# STM32G474xx register map
File version: 1.4
CPU: CM4 r0p1, little endian, MPU, FPU, 4 interrupt priority bits
Registers are 32-bit, read-write, reset 0x0 unless marked. A register's access mark holds for its fields unless they carry their own. Offsets are from the block's base; [hi:lo] are bit positions; {n}, {i} and the like mark numbered series.

## FMAC — Filter Math Accelerator
Base 0x40021400
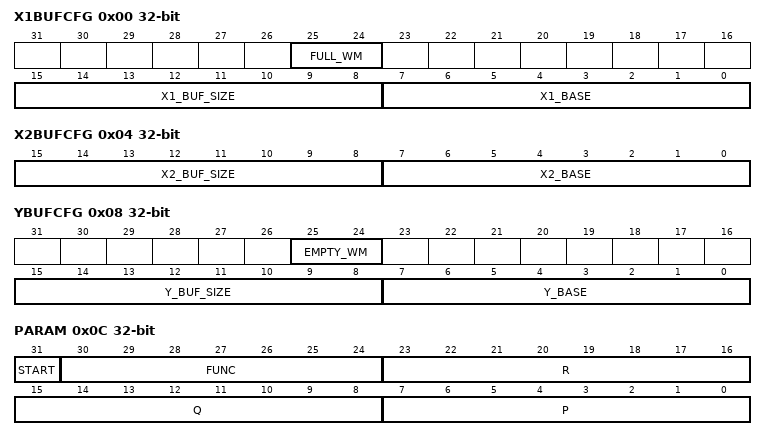
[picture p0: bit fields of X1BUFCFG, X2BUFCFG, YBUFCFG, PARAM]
0x00 X1BUFCFG — FMAC X1 Buffer Configuration register
  [25:24] FULL_WM, [15:8] X1_BUF_SIZE, [7:0] X1_BASE
0x04 X2BUFCFG — FMAC X2 Buffer Configuration register
  [15:8] X2_BUF_SIZE — X1_BUF_SIZE
  [7:0] X2_BASE — X1_BASE
0x08 YBUFCFG — FMAC Y Buffer Configuration register
  [25:24] EMPTY_WM
  [15:8] Y_BUF_SIZE — X1_BUF_SIZE
  [7:0] Y_BASE — X1_BASE
0x0C PARAM — FMAC Parameter register
  [31] START, [30:24] FUNC, [23:16] R, [15:8] Q, [7:0] P
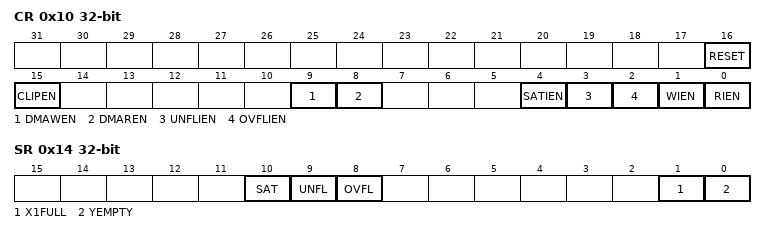
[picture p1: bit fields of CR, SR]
0x10 CR — FMAC Control register
  [16] RESET, [15] CLIPEN, [9] DMAWEN, [8] DMAREN, [4] SATIEN, [3] UNFLIEN, [2] OVFLIEN, [1] WIEN, [0] RIEN
0x14 SR ro — FMAC Status register
  [10] SAT, [9] UNFL, [8] OVFL, [1] X1FULL, [0] YEMPTY
0x18 WDATA wo — FMAC Write Data register
  [15:0] WDATA
0x1C RDATA ro — FMAC Read Data register
  [15:0] RDATA

## CORDIC — CORDIC Co-processor
Base 0x40020C00
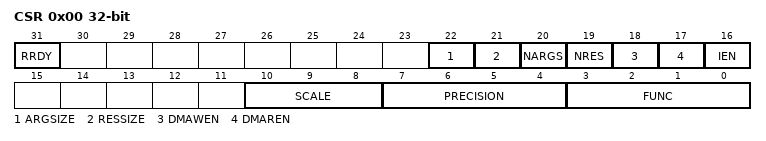
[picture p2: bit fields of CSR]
0x00 CSR — CORDIC Control Status register
  [31] RRDY, [22] ARGSIZE, [21] RESSIZE, [20] NARGS, [19] NRES, [18] DMAWEN, [17] DMAREN, [16] IEN, [10:8] SCALE, [7:4] PRECISION, [3:0] FUNC
0x04 WDATA — FMAC Write Data register
  [31:0] ARG
0x08 RDATA ro — FMAC Read Data register
  [31:0] RES

## TAMP — Tamper and backup registers
Base 0x40002400
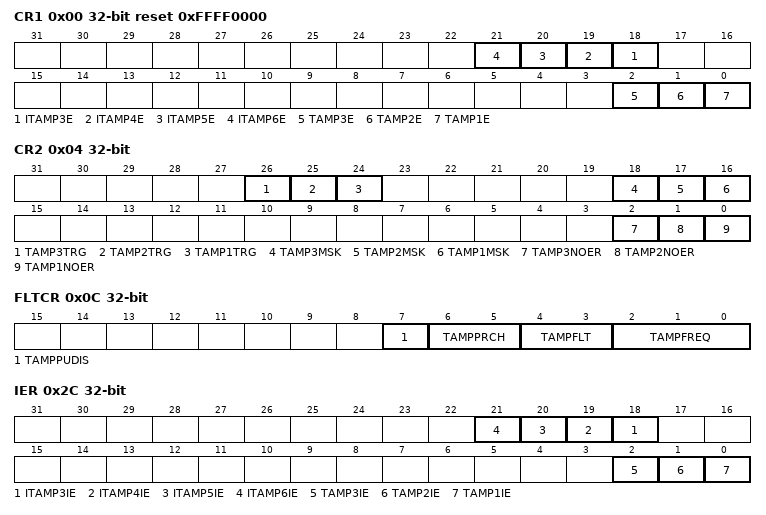
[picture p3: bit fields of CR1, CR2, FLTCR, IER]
0x00 CR1 reset 0xFFFF0000 — control register 1
  [n+15] ITAMP{n}E (n=3..6)
  [2] TAMP3E — TAMP2E
  [1] TAMP2E
  [0] TAMP1E
0x04 CR2 — control register 2
  [26] TAMP3TRG, [25] TAMP2TRG, [24] TAMP1TRG, [18] TAMP3MSK, [17] TAMP2MSK, [16] TAMP1MSK, [2] TAMP3NOER, [1] TAMP2NOER, [0] TAMP1NOER
0x0C FLTCR — TAMP filter control register
  [7] TAMPPUDIS, [6:5] TAMPPRCH, [4:3] TAMPFLT, [2:0] TAMPFREQ
0x2C IER — TAMP interrupt enable register
  [n+15] ITAMP{n}IE (n=3..6), [2] TAMP3IE, [1] TAMP2IE, [0] TAMP1IE
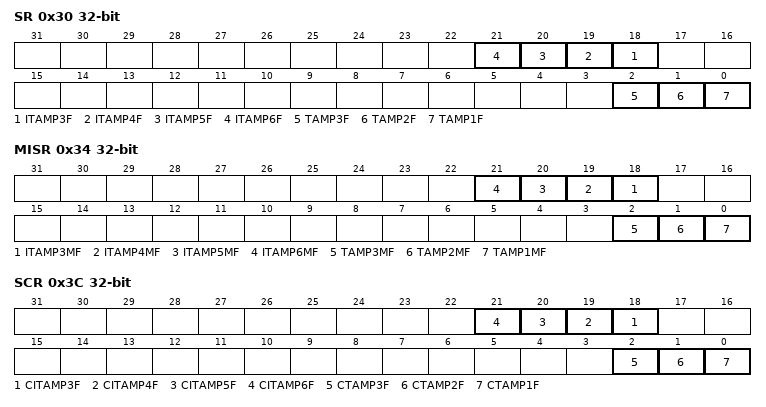
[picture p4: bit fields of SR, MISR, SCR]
0x30 SR ro — TAMP status register
  [n+15] ITAMP{n}F (n=3..6), [2] TAMP3F, [1] TAMP2F, [0] TAMP1F
0x34 MISR ro — TAMP masked interrupt status register
  [n+15] ITAMP{n}MF (n=3..6), [2] TAMP3MF, [1] TAMP2MF, [0] TAMP1MF
0x3C SCR — TAMP status clear register
  [n+15] CITAMP{n}F (n=3..6), [2] CTAMP3F, [1] CTAMP2F, [0] CTAMP1F
{0x100+4i} BKP{i}R (i=0..31) — TAMP backup register
  [31:0] BKP

## FPU — Floting point unit
Base 0xE000EF34
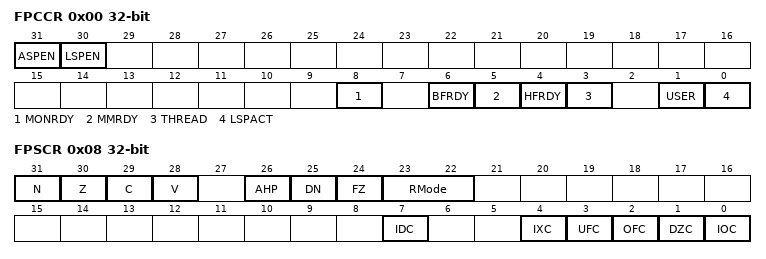
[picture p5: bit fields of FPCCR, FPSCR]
0x00 FPCCR — Floating-point context control register
  [31] ASPEN, [30] LSPEN, [8] MONRDY, [6] BFRDY, [5] MMRDY, [4] HFRDY, [3] THREAD, [1] USER, [0] LSPACT
0x04 FPCAR — Floating-point context address register
  [31:3] ADDRESS — Location of unpopulated floating-point
0x08 FPSCR — Floating-point status control register
  [31] N — Negative condition code flag
  [30] Z — Zero condition code flag
  [29] C — Carry condition code flag
  [28] V — Overflow condition code flag
  [26] AHP — Alternative half-precision control bit
  [25] DN — Default NaN mode control bit
  [24] FZ — Flush-to-zero mode control bit:
  [23:22] RMode — Rounding Mode control field
  [7] IDC — Input denormal cumulative exception bit.
  [4] IXC — Inexact cumulative exception bit
  [3] UFC — Underflow cumulative exception bit
  [2] OFC — Overflow cumulative exception bit
  [1] DZC — Division by zero cumulative exception bit.
  [0] IOC — Invalid operation cumulative exception bit

## MPU — Memory protection unit
Base 0xE000E084
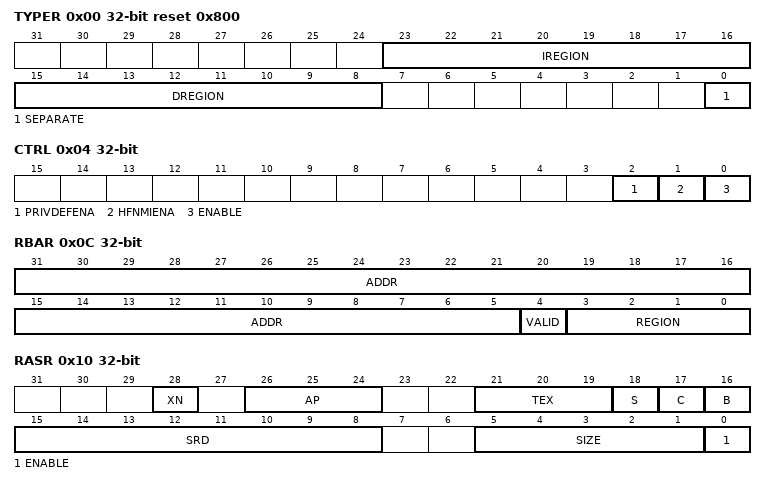
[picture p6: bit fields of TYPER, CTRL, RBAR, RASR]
0x00 TYPER ro reset 0x800 — MPU type register
  [23:16] IREGION — Number of MPU instruction regions
  [15:8] DREGION — Number of MPU data regions
  [0] SEPARATE — Separate flag
0x04 CTRL — MPU control register
  [2] PRIVDEFENA — Enable priviliged software access to default memory map
  [1] HFNMIENA — Enables the operation of MPU during hard fault
  [0] ENABLE — Enables the MPU
0x08 RNR — MPU region number register
  [7:0] REGION — MPU region
0x0C RBAR — MPU region base address register
  [31:5] ADDR — Region base address field
  [4] VALID — MPU region number valid
  [3:0] REGION — MPU region field
0x10 RASR — MPU region attribute and size register
  [28] XN — Instruction access disable bit
  [26:24] AP — Access permission
  [21:19] TEX — memory attribute
  [18] S — Shareable memory attribute
  [17] C — memory attribute
  [16] B — memory attribute
  [15:8] SRD — Subregion disable bits
  [5:1] SIZE — Size of the MPU protection region
  [0] ENABLE — Region enable bit.
